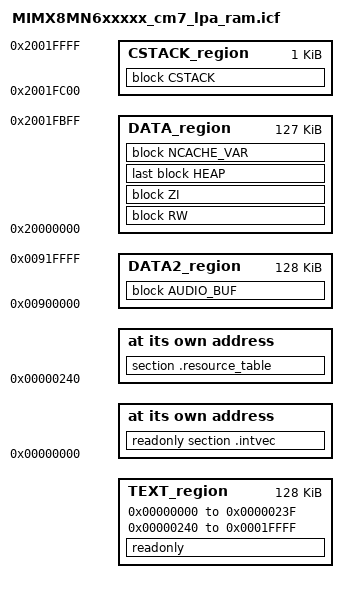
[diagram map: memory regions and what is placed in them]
/*
** ###################################################################
**     Processors:          MIMX8MN6CVTIZ
**                          MIMX8MN6DVTJZ
**
**     Compiler:            IAR ANSI C/C++ Compiler for ARM
**     Reference manual:    MX8MNRM, Rev.A, 04/2019
**     Version:             rev. 1.0, 2019-04-22
**     Build:               b190509
**
**     Abstract:
**         Linker file for the IAR ANSI C/C++ Compiler for ARM
**
**     Copyright 2016 Freescale Semiconductor, Inc.
**     Copyright 2016-2019 NXP
**     All rights reserved.
**
**     SPDX-License-Identifier: BSD-3-Clause
**
**     http:                 www.nxp.com
**     mail:                 support@nxp.com
**
** ###################################################################
*/


define symbol m_interrupts_start       = 0x00000000;
define symbol m_interrupts_end         = 0x0000023F;

define symbol m_text_start             = 0x00000240;
define symbol m_text_end               = 0x0001FFFF;

define symbol m_data_start             = 0x20000000;
define symbol m_data_end               = 0x2001FFFF;

define symbol m_data2_start            = 0x00900000;
define symbol m_data2_end              = 0x0091FFFF; 

/* Sizes */
if (isdefinedsymbol(__stack_size__)) {
  define symbol __size_cstack__        = __stack_size__;
} else {
  define symbol __size_cstack__        = 0x0400;
}

if (isdefinedsymbol(__heap_size__)) {
  define symbol __size_heap__          = __heap_size__;
} else {
  define symbol __size_heap__          = 0x0400;
}

define exported symbol __CACHE_REGION_START   = m_interrupts_start;
define exported symbol __CACHE_REGION_SIZE    = 0x0;

define memory mem with size = 4G;
define region TEXT_region = mem:[from m_interrupts_start to m_interrupts_end]
                          | mem:[from m_text_start to m_text_end];
define region DATA_region = mem:[from m_data_start to m_data_end-__size_cstack__];
define region CSTACK_region = mem:[from m_data_end-__size_cstack__+1 to m_data_end];
define region DATA2_region = mem:[from m_data2_start to m_data2_end];

define block CSTACK    with alignment = 8, size = __size_cstack__   { };
define block HEAP      with alignment = 8, size = __size_heap__     { };
define block RW        { readwrite };
define block ZI        { zi };
define block NCACHE_VAR { section NonCacheable , section NonCacheable.init };
define block AUDIO_BUF {section AudioBuf};

initialize by copy { readwrite, section .textrw };
do not initialize  { section .noinit };
keep{section .resource_table};

place at address mem: m_interrupts_start    { readonly section .intvec };
".resource_table": place at address mem: m_text_start {section .resource_table};
place in TEXT_region                        { readonly };
place in DATA_region                        { block RW };
place in DATA_region                        { block ZI };
place in DATA_region                        { last block HEAP };
place in CSTACK_region                      { block CSTACK };
place in DATA_region                        { block NCACHE_VAR };
place in DATA2_region                       { block AUDIO_BUF };
